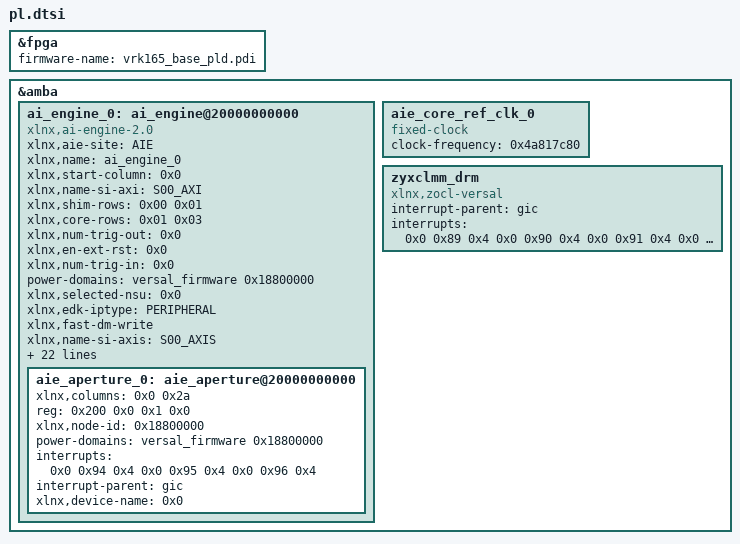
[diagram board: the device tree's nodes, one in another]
/dts-v1/;
/plugin/;

&fpga {
        firmware-name = "vrk165_base_pld.pdi";
};

&amba {

        ai_engine_0: ai_engine@20000000000 {
                xlnx,aie-site = "AIE";
                xlnx,name = "ai_engine_0";
                xlnx,start-column = <0x0>;
                xlnx,name-si-axi = "S00_AXI";
                xlnx,shim-rows = /bits/ 8 <0x00 0x01>;
                xlnx,core-rows = /bits/ 8 <0x01 0x03>;
                xlnx,num-trig-out = <0x0>;
                xlnx,en-ext-rst = <0x0>;
                xlnx,num-trig-in = <0x0>;
                power-domains = <&versal_firmware 0x18800000>;
                clock-names = "aclk0";
                xlnx,selected-nsu = <0x0>;
                xlnx,edk-iptype = "PERIPHERAL";
                xlnx,fast-dm-write;
                xlnx,name-si-axis = "S00_AXIS";
                xlnx,clk-names = "aclk0";
                xlnx,aie-core-ref-ctrl-freqmhz = <0x4e2>;
                xlnx,num-column = <0x1>;
                xlnx,name-mi-axi = "M00_AXI";
                xlnx,num-si-axis = <0x0>;
                #address-cells = <0x2>;
                xlnx,partition-enabled = <0x0>;
                xlnx,num-clks = <0x0>;
                ranges;
                xlnx,num-noc-axis-clks = <0x0>;
                clocks = <&aie_core_ref_clk_0>;
                reg = <0x200 0x0 0x1 0x0>;
                xlnx,fast-pm-write;
                xlnx,num-si-axi = <0x1>;
                #size-cells = <0x2>;
                xlnx,ip-name = "ai_engine";
                xlnx,mi-destid-pins;
                xlnx,mem-rows = /bits/ 8 <0x00 0x00>;
                xlnx,name-mi-axis = "M00_AXIS";
                xlnx,aie-gen = [01];
                xlnx,en-addr-virtualization = <0x0>;
                xlnx,aie-max-freq = <0x4e2>;
                xlnx,num-mi-axis = <0x0>;
                xlnx,aie-ref-clk-freqmhz = <0x1fc9f08>;
                compatible = "xlnx,ai-engine-2.0", "xlnx,ai-engine-v2.0";
                xlnx,num-mi-axi = <0x0>;

                aie_aperture_0: aie_aperture@20000000000 {
                        xlnx,columns = <0x0 0x2a>;
                        reg = <0x200 0x0 0x1 0x0>;
                        interrupt-names = "interrupt1", "interrupt2", "interrupt3";
                        #size-cells = <0x2>;
                        xlnx,node-id = <0x18800000>;
                        power-domains = <&versal_firmware 0x18800000>;
                        #address-cells = <0x2>;
                        interrupts = <0x0 0x94 0x4 0x0 0x95 0x4 0x0 0x96 0x4>;
                        interrupt-parent = <&gic>;
                        xlnx,device-name = <0x0>;
                };
        };

        aie_core_ref_clk_0: aie_core_ref_clk_0 {
                #clock-cells = <0x0>;
                clock-frequency = <0x4a817c80>;
                compatible = "fixed-clock";
        };

        zyxclmm_drm {
                compatible = "xlnx,zocl-versal";
                interrupt-parent = <&gic>;
                interrupts = <0x0 0x89 0x4 0x0 0x90 0x4 0x0 0x91 0x4 0x0 0x92 0x4 0x0 0x93 0x4 0x0 0x94 0x4 0x0 0x95 0x4 0x0 0x96 0x4>;
        };
};

